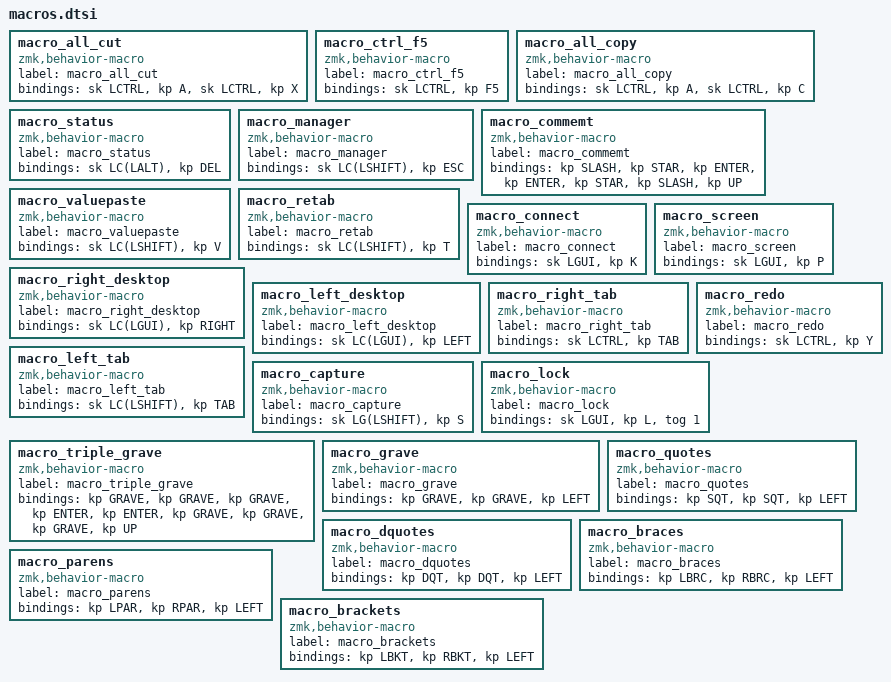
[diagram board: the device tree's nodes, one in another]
macro_all_cut: macro_all_cut{
compatible = "zmk,behavior-macro";
label = "macro_all_cut";
#binding-cells = <0>;
bindings = <&sk LCTRL>, <&kp A>, <&sk LCTRL>, <&kp X>;
};
macro_ctrl_f5: macro_ctrl_f5{
compatible = "zmk,behavior-macro";
label = "macro_ctrl_f5";
#binding-cells = <0>;
bindings = <&sk LCTRL>, <&kp F5>;
};
macro_all_copy: macro_all_copy{
compatible = "zmk,behavior-macro";
label = "macro_all_copy";
#binding-cells = <0>;
bindings = <&sk LCTRL>, <&kp A>, <&sk LCTRL>, <&kp C>;
};
macro_status: macro_status{
compatible = "zmk,behavior-macro";
label = "macro_status";
#binding-cells = <0>;
bindings = <&sk LC(LALT)>, <&kp DEL>;
};
macro_manager: macro_manager{
compatible = "zmk,behavior-macro";
label = "macro_manager";
#binding-cells = <0>;
bindings = <&sk LC(LSHIFT)>, <&kp ESC>;
};
macro_commemt: macro_commemt{
compatible = "zmk,behavior-macro";
label = "macro_commemt";
#binding-cells = <0>;
bindings = <&kp SLASH>, <&kp STAR>, <&kp ENTER>, <&kp ENTER>, <&kp STAR>, <&kp SLASH>, <&kp UP>;
};
macro_valuepaste: macro_valuepaste{
compatible = "zmk,behavior-macro";
label = "macro_valuepaste";
#binding-cells = <0>;
bindings = <&sk LC(LSHIFT)>, <&kp V>;
};
macro_retab: macro_retab{
compatible = "zmk,behavior-macro";
label = "macro_retab";
#binding-cells = <0>;
bindings = <&sk LC(LSHIFT)>, <&kp T>;
};
macro_connect: macro_connect{
compatible = "zmk,behavior-macro";
label = "macro_connect";
#binding-cells = <0>;
bindings = <&sk LGUI>, <&kp K>;
};
macro_screen: macro_screen{
compatible = "zmk,behavior-macro";
label = "macro_screen";
#binding-cells = <0>;
bindings = <&sk LGUI>, <&kp P>;
};
macro_right_desktop: macro_right_desktop{
compatible = "zmk,behavior-macro";
label = "macro_right_desktop";
#binding-cells = <0>;
bindings = <&sk LC(LGUI)>, <&kp RIGHT>;
};
macro_left_desktop: macro_left_desktop{
compatible = "zmk,behavior-macro";
label = "macro_left_desktop";
#binding-cells = <0>;
bindings = <&sk LC(LGUI)>, <&kp LEFT>;
};
macro_right_tab: macro_right_tab{
compatible = "zmk,behavior-macro";
label = "macro_right_tab";
#binding-cells = <0>;
bindings = <&sk LCTRL>, <&kp TAB>;
};
macro_left_tab: macro_left_tab{
compatible = "zmk,behavior-macro";
label = "macro_left_tab";
#binding-cells = <0>;
bindings = <&sk LC(LSHIFT)>, <&kp TAB>;
};
macro_redo: macro_redo{
compatible = "zmk,behavior-macro";
label = "macro_redo";
#binding-cells = <0>;
bindings = <&sk LCTRL>, <&kp Y>;
};
macro_capture: macro_capture{
compatible = "zmk,behavior-macro";
label = "macro_capture";
#binding-cells = <0>;
bindings = <&sk LG(LSHIFT)>, <&kp S>;
};
macro_lock: macro_lock{
compatible = "zmk,behavior-macro";
label = "macro_lock";
#binding-cells = <0>;
bindings = <&sk LGUI>, <&kp L>, <&tog 1>;
};
macro_triple_grave: macro_triple_grave{
compatible = "zmk,behavior-macro";
label = "macro_triple_grave";
#binding-cells = <0>;
bindings = <&kp GRAVE>, <&kp GRAVE>, <&kp GRAVE>, <&kp ENTER>, <&kp ENTER>, <&kp GRAVE>, <&kp GRAVE>, <&kp GRAVE>, <&kp UP>;
};
macro_grave: macro_grave{
compatible = "zmk,behavior-macro";
label = "macro_grave";
#binding-cells = <0>;
bindings = <&kp GRAVE>, <&kp GRAVE>, <&kp LEFT>;
};
macro_quotes: macro_quotes{
compatible = "zmk,behavior-macro";
label = "macro_quotes";
#binding-cells = <0>;
bindings = <&kp SQT>, <&kp SQT>, <&kp LEFT>;
};
macro_dquotes: macro_dquotes{
compatible = "zmk,behavior-macro";
label = "macro_dquotes";
#binding-cells = <0>;
bindings = <&kp DQT>, <&kp DQT>, <&kp LEFT>;
};
macro_braces: macro_braces{
compatible = "zmk,behavior-macro";
label = "macro_braces";
#binding-cells = <0>;
bindings = <&kp LBRC>, <&kp RBRC>, <&kp LEFT>;
};
macro_parens: macro_parens{
compatible = "zmk,behavior-macro";
label = "macro_parens";
#binding-cells = <0>;
bindings = <&kp LPAR>, <&kp RPAR>, <&kp LEFT>;
};
macro_brackets: macro_brackets{
compatible = "zmk,behavior-macro";
label = "macro_brackets";
#binding-cells = <0>;
bindings = <&kp LBKT>, <&kp RBKT>, <&kp LEFT>;
};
